# CY8C5888LTI_LP097 register map
File version: 0.1
CY8C58LP
Registers are 8-bit, read-write, no defined reset value unless marked. A register's access mark holds for its fields unless they carry their own. Offsets are from the block's base; lines under a group give offsets from that group; [hi:lo] are bit positions; {n}, {i} and the like mark numbered series; 'fields as' and 'values as' point back to an identical list; <NAME> marks a mode.

## Memory map
0x00000000 I2C
0x00000000 UART
0x4000646D via8bits_P0_stat
0x40006479 via8bits_gnome_clk
0x4000647D via8bits_P0_ctrl
0x40006564 LCD_gnome_A_reg
0x40006565 LCD_gnome_B_reg
0x40006569 via8bits_P1_stat
0x40006578 via8bits_Ctrl
0x40006579 via8bits_P1_ctrl

## UART
Base 0x00000000
0x4000654B TX_UART_TX_DATA — TX Data Register
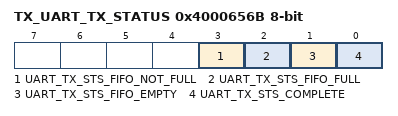
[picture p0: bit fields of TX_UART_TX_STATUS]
0x4000656B TX_UART_TX_STATUS — TX status register
  [3] UART_TX_STS_FIFO_NOT_FULL ro, [2] UART_TX_STS_FIFO_FULL ro, [1] UART_TX_STS_FIFO_EMPTY ro, [0] UART_TX_STS_COMPLETE ro

## LCD_gnome_B_reg
Base 0x40006565
0x00 LCD_gnome_B_reg_STATUS_REG
0x20 LCD_gnome_B_reg_MASK_REG
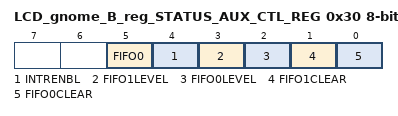
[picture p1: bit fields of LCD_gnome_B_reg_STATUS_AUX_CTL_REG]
0x30 LCD_gnome_B_reg_STATUS_AUX_CTL_REG
  [5] FIFO0 — FIFO0 clear
    1=ENABLED (Enable counter); 0=DISABLED (Disable counter)
  [4] INTRENBL — Enables or disables the Interrupt
    1=ENABLED (Interrupt enabled); 0=DISABLED (Interrupt disabled)
  [3] FIFO1LEVEL — FIFO level
    1=ENABLED (FIFO LVL: input mode: FIFO at least 1/2 empty; output mode: FIFO at least 1/2 full); 0=DISABLED (FIFO LVL: input mode: FIFO not full; output mode: FIFO not empty)
  [2] FIFO0LEVEL — FIFO level
    values as FIFO1LEVEL
  [1] FIFO1CLEAR — FIFO clear
    1=ENABLED (Clear FIFO state); 0=DISABLED (Normal FIFO operation)
  [0] FIFO0CLEAR — FIFO clear
    values as FIFO1CLEAR

## LCD_gnome_A_reg
Base 0x40006564
Registers as LCD_gnome_B_reg (with LCD_gnome_B_reg read as LCD_gnome_A_reg).

## via8bits_P1_stat
Base 0x40006569
Registers as LCD_gnome_B_reg (with LCD_gnome_B_reg read as via8bits_P1_stat).

## via8bits_P0_stat
Base 0x4000646D
Registers as LCD_gnome_B_reg (with LCD_gnome_B_reg read as via8bits_P0_stat).

## via8bits_gnome_clk
Base 0x40006479
0x00 via8bits_gnome_clk_CONTROL_REG

## via8bits_P1_ctrl
Base 0x40006579
Registers as via8bits_gnome_clk (with via8bits_gnome_clk read as via8bits_P1_ctrl).

## via8bits_Ctrl
Base 0x40006578
Registers as via8bits_gnome_clk (with via8bits_gnome_clk read as via8bits_Ctrl).

## via8bits_P0_ctrl
Base 0x4000647D
Registers as via8bits_gnome_clk (with via8bits_gnome_clk read as via8bits_P0_ctrl).
